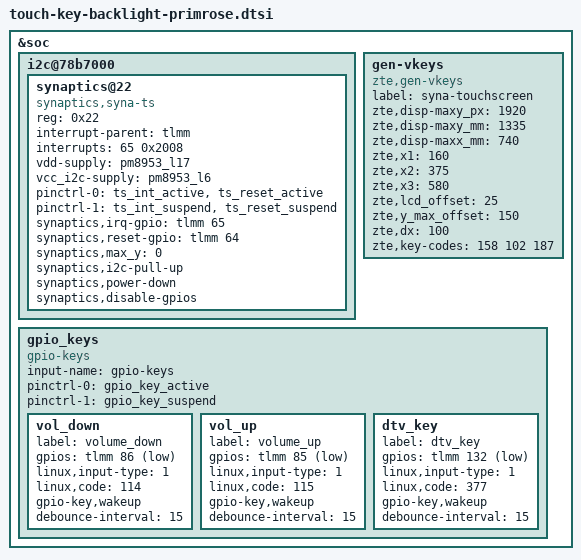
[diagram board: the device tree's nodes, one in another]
&soc {
	i2c@78b7000 {
		status = "okay";
		synaptics@22 {
			compatible = "synaptics,syna-ts";
			reg = <0x22>;
			interrupt-parent = <&tlmm>;
			interrupts = <65 0x2008>;
			vdd-supply = <&pm8953_l17>;
			vcc_i2c-supply = <&pm8953_l6>;
			pinctrl-names = "pmx_ts_active","pmx_ts_suspend";
			pinctrl-0 = <&ts_int_active &ts_reset_active>;
			pinctrl-1 = <&ts_int_suspend &ts_reset_suspend>;
			synaptics,irq-gpio = <&tlmm 65 0x2008>;
			synaptics,reset-gpio = <&tlmm 64 0x0>;
			synaptics,max_y = <0>;
			synaptics,i2c-pull-up;
			synaptics,power-down;
			synaptics,disable-gpios;
		};
	};

	gen-vkeys {
		compatible = "zte,gen-vkeys";
		label = "syna-touchscreen";
		zte,disp-maxy_px = <1920>;
		zte,disp-maxy_mm = <1335>;
		zte,disp-maxx_mm = <740>;
		zte,x1=<160>;
		zte,x2=<375>;
		zte,x3=<580>;
		zte,lcd_offset=<25>;
		zte,y_max_offset=<150>;
		zte,dx=<100>;
		zte,key-codes = <158 102 187>;
	};

	gpio_keys {
		compatible = "gpio-keys";
		input-name = "gpio-keys";
		pinctrl-names = "tlmm_gpio_key_active","tlmm_gpio_key_suspend";
		pinctrl-0 = <&gpio_key_active>;
		pinctrl-1 = <&gpio_key_suspend>;

		vol_down {
			label = "volume_down";
			gpios = <&tlmm 86 0x1>;
			linux,input-type = <1>;
			linux,code = <114>;
			gpio-key,wakeup;
			debounce-interval = <15>;
		};
		vol_up {
			label = "volume_up";
			gpios = <&tlmm 85 0x1>;
			linux,input-type = <1>;
			linux,code = <115>;
			gpio-key,wakeup;
			debounce-interval = <15>;
		};
		dtv_key {
			label = "dtv_key";
			gpios = <&tlmm 132 0x1>;
			linux,input-type = <1>;
			linux,code = <377>;
			gpio-key,wakeup;
			debounce-interval = <15>;
		};
	};
};
